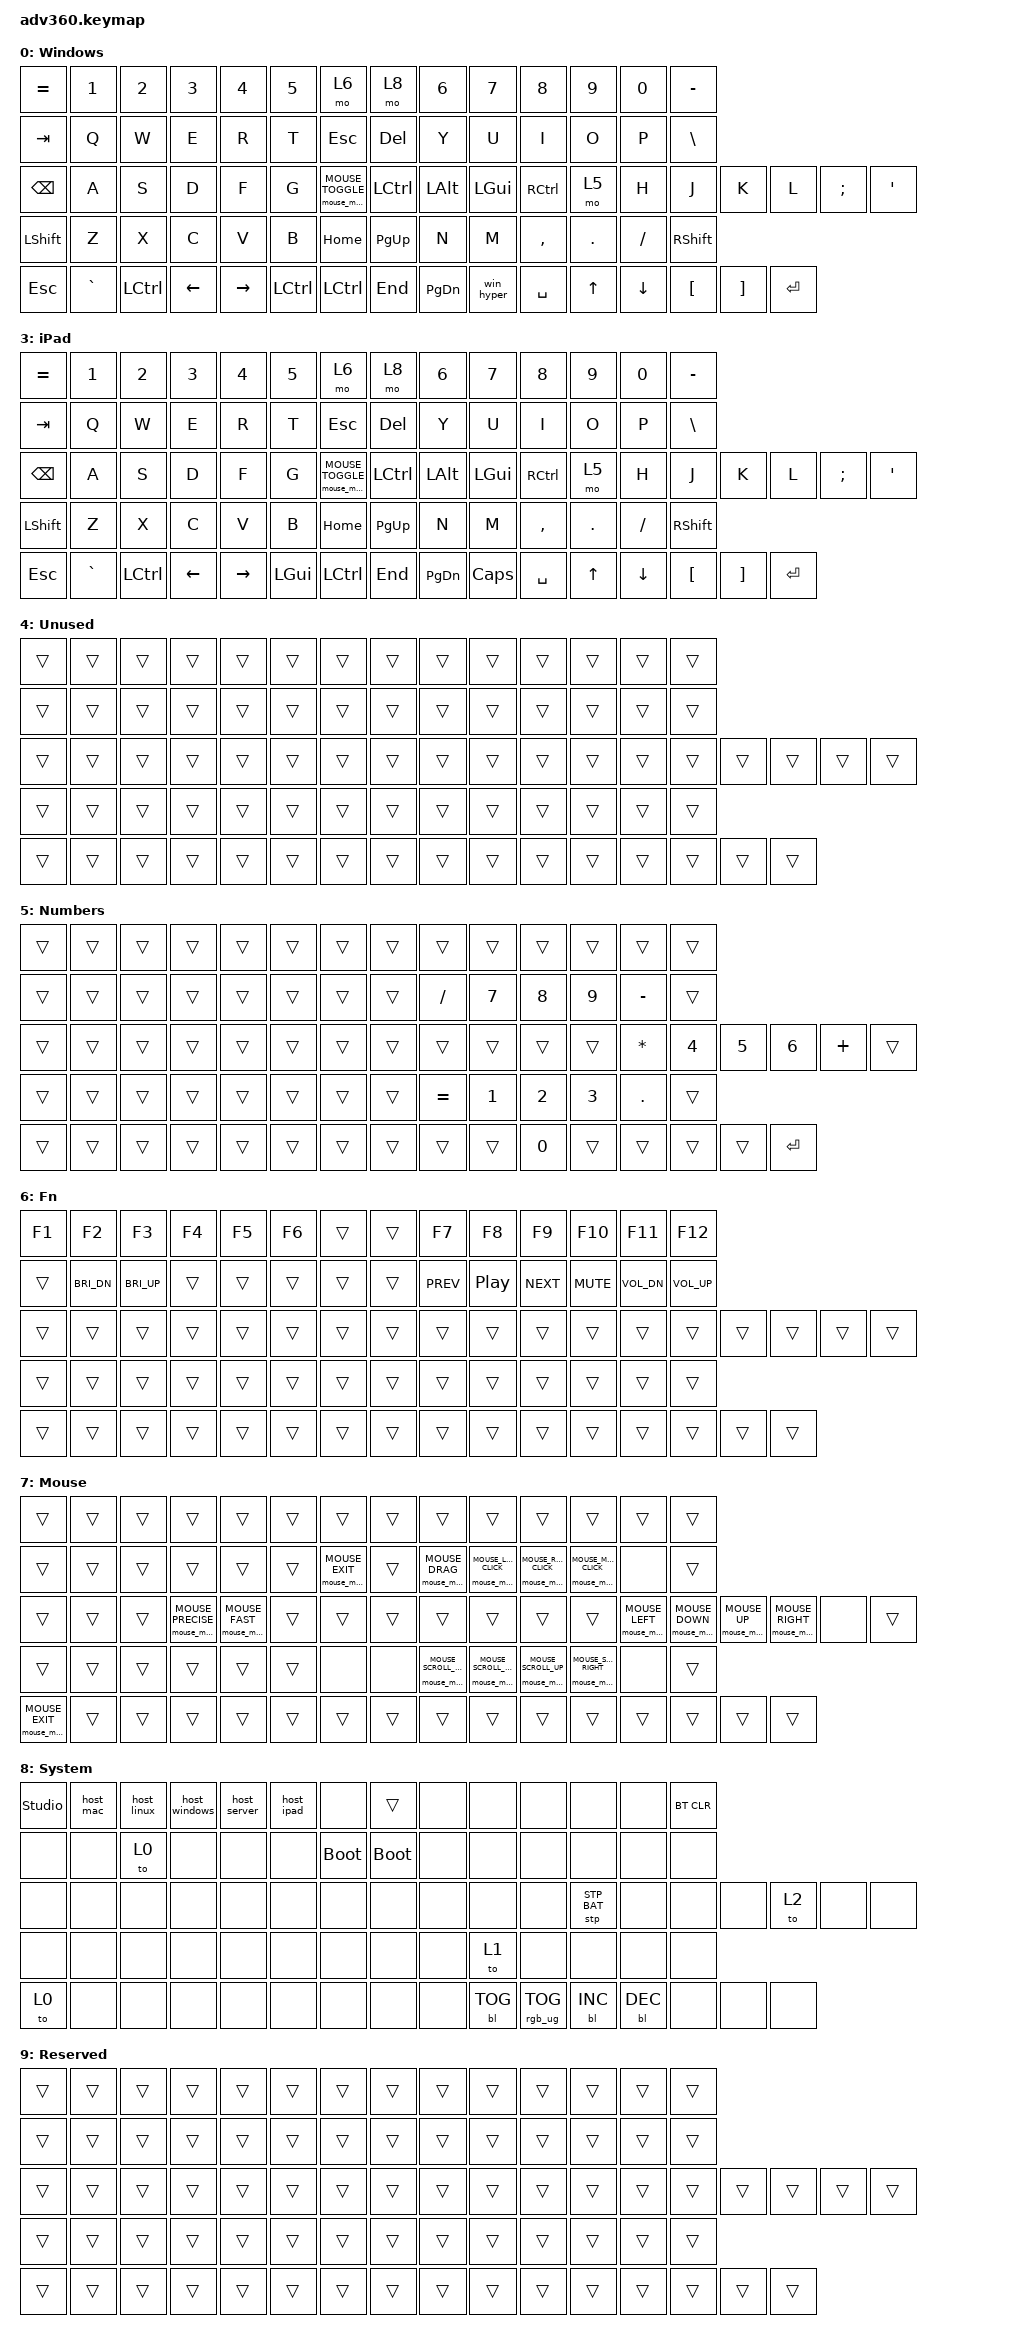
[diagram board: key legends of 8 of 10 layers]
// USER-APPROVED LAYOUT: device keys 1=Mac, 2=Linux, 3=Windows, 4=Linux server, 5=iPad.
// The boot default is Windows (no GUI in Hyper). Reselect a device after power-on.
// No tap-hold timing, no letter chords, Mouse is toggled; other utility layers are momentary.
#include <dt-bindings/zmk/stp.h>
#include <behaviors.dtsi>
#include <dt-bindings/zmk/backlight.h>
#include <dt-bindings/zmk/bt.h>
#include <dt-bindings/zmk/keys.h>
#include <dt-bindings/zmk/pointing.h>
#include <dt-bindings/zmk/mouse-mode.h>
#include <dt-bindings/zmk/rgb.h>

/ {
    mouse_precise_listener {
        compatible = "zmk,input-listener";
        device = <&mouse_precise_motion>;
    };
    mouse_fast_listener {
        compatible = "zmk,input-listener";
        device = <&mouse_fast_motion>;
    };
    behaviors {
        mouse_precise_motion: mouse_precise_motion {
            compatible = "zmk,behavior-input-two-axis";
            #binding-cells = <1>;
            x-input-code = <INPUT_REL_X>;
            y-input-code = <INPUT_REL_Y>;
            time-to-max-speed-ms = <0>;
            acceleration-exponent = <0>;
        };
        mouse_fast_motion: mouse_fast_motion {
            compatible = "zmk,behavior-input-two-axis";
            #binding-cells = <1>;
            x-input-code = <INPUT_REL_X>;
            y-input-code = <INPUT_REL_Y>;
            time-to-max-speed-ms = <0>;
            acceleration-exponent = <0>;
        };
        mouse_mode: mouse_mode {
            compatible = "zmk,behavior-mouse-mode";
            #binding-cells = <1>;
            layer = <7>;
            movement-behavior = <&mmv>;
            precise-behavior = <&mouse_precise_motion>;
            fast-behavior = <&mouse_fast_motion>;
            scroll-behavior = <&msc>;
        };
    };
    macros {
        // Hold real modifiers until the thumb is released. Modified F24 uses
        // implicit modifiers, which ZMK clears when another key is pressed.
        win_hyper: win_hyper {
            compatible = "zmk,behavior-macro";
            #binding-cells = <0>;
            wait-ms = <0>;
            tap-ms = <0>;
            bindings = <&macro_press &kp LCTRL &kp LSHFT &kp LALT &kp F24>,
                       <&macro_pause_for_release>,
                       <&macro_release &kp F24 &kp LALT &kp LSHFT &kp LCTRL>;
        };
        host_mac: host_mac {
            compatible = "zmk,behavior-macro";
            #binding-cells = <0>;
            wait-ms = <0>;
            tap-ms = <0>;
            // Release drag before changing the Bluetooth destination.
            bindings = <&macro_wait_time 50 &mouse_mode MOUSE_EXIT>,
                       <&macro_wait_time 0 &bt BT_SEL 0>, <&to 1>;
        };
        host_linux: host_linux {
            compatible = "zmk,behavior-macro";
            #binding-cells = <0>;
            wait-ms = <0>;
            tap-ms = <0>;
            // Release drag before changing the Bluetooth destination.
            bindings = <&macro_wait_time 50 &mouse_mode MOUSE_EXIT>,
                       <&macro_wait_time 0 &bt BT_SEL 1>, <&to 2>;
        };
        host_windows: host_windows {
            compatible = "zmk,behavior-macro";
            #binding-cells = <0>;
            wait-ms = <0>;
            tap-ms = <0>;
            // Release drag before changing the Bluetooth destination.
            bindings = <&macro_wait_time 50 &mouse_mode MOUSE_EXIT>,
                       <&macro_wait_time 0 &bt BT_SEL 2>, <&to 0>;
        };
        host_server: host_server {
            compatible = "zmk,behavior-macro";
            #binding-cells = <0>;
            wait-ms = <0>;
            tap-ms = <0>;
            // Release drag before changing the Bluetooth destination.
            bindings = <&macro_wait_time 50 &mouse_mode MOUSE_EXIT>,
                       <&macro_wait_time 0 &bt BT_SEL 3>, <&to 2>;
        };
        host_ipad: host_ipad {
            compatible = "zmk,behavior-macro";
            #binding-cells = <0>;
            wait-ms = <0>;
            tap-ms = <0>;
            // Slot 5 owns the iPad base; release mouse actions before switching.
            bindings = <&macro_wait_time 50 &mouse_mode MOUSE_EXIT>,
                       <&macro_wait_time 0 &bt BT_SEL 4>, <&to 3>;
        };
    };
    keymap {
        compatible = "zmk,keymap";
        windows {
            display-name = "Windows";
            bindings = <
                &kp EQUAL  &kp N1  &kp N2  &kp N3  &kp N4  &kp N5  &mo 6  &mo 8  &kp N6  &kp N7  &kp N8  &kp N9  &kp N0  &kp MINUS
                &kp TAB  &kp Q  &kp W  &kp E  &kp R  &kp T  &kp ESCAPE  &kp DELETE  &kp Y  &kp U  &kp I  &kp O  &kp P  &kp BSLH
                &kp BACKSPACE  &kp A  &kp S  &kp D  &kp F  &kp G  &mouse_mode MOUSE_TOGGLE  &kp LCTRL  &kp LALT  &kp LGUI  &kp RCTRL  &mo 5  &kp H  &kp J  &kp K  &kp L  &kp SEMI  &kp SQT
                &kp LSHFT  &kp Z  &kp X  &kp C  &kp V  &kp B  &kp HOME  &kp PG_UP  &kp N  &kp M  &kp COMMA  &kp DOT  &kp FSLH  &kp RSHFT
                &kp ESCAPE  &kp GRAVE  &kp LCTRL  &kp LEFT  &kp RIGHT  &kp LCTRL  &kp LCTRL  &kp END  &kp PG_DN  &win_hyper  &kp SPACE  &kp UP  &kp DOWN  &kp LBKT  &kp RBKT  &kp RETURN
            >;
        };
        macos {
            display-name = "Mac";
            bindings = <
                &kp EQUAL  &kp N1  &kp N2  &kp N3  &kp N4  &kp N5  &mo 6  &mo 8  &kp N6  &kp N7  &kp N8  &kp N9  &kp N0  &kp MINUS
                &kp TAB  &kp Q  &kp W  &kp E  &kp R  &kp T  &kp ESCAPE  &kp DELETE  &kp Y  &kp U  &kp I  &kp O  &kp P  &kp BSLH
                &kp BACKSPACE  &kp A  &kp S  &kp D  &kp F  &kp G  &mouse_mode MOUSE_TOGGLE  &kp LCTRL  &kp LALT  &kp LGUI  &kp RCTRL  &mo 5  &kp H  &kp J  &kp K  &kp L  &kp SEMI  &kp SQT
                &kp LSHFT  &kp Z  &kp X  &kp C  &kp V  &kp B  &kp HOME  &kp PG_UP  &kp N  &kp M  &kp COMMA  &kp DOT  &kp FSLH  &kp RSHFT
                &kp ESCAPE  &kp GRAVE  &kp LCTRL  &kp LEFT  &kp RIGHT  &kp LGUI  &kp LCTRL  &kp END  &kp PG_DN  &kp LS(LC(LA(LGUI)))  &kp SPACE  &kp UP  &kp DOWN  &kp LBKT  &kp RBKT  &kp RETURN
            >;
        };
        linux {
            display-name = "Linux";
            bindings = <
                &kp EQUAL  &kp N1  &kp N2  &kp N3  &kp N4  &kp N5  &mo 6  &mo 8  &kp N6  &kp N7  &kp N8  &kp N9  &kp N0  &kp MINUS
                &kp TAB  &kp Q  &kp W  &kp E  &kp R  &kp T  &kp ESCAPE  &kp DELETE  &kp Y  &kp U  &kp I  &kp O  &kp P  &kp BSLH
                &kp BACKSPACE  &kp A  &kp S  &kp D  &kp F  &kp G  &mouse_mode MOUSE_TOGGLE  &kp LCTRL  &kp LALT  &kp LGUI  &kp RCTRL  &mo 5  &kp H  &kp J  &kp K  &kp L  &kp SEMI  &kp SQT
                &kp LSHFT  &kp Z  &kp X  &kp C  &kp V  &kp B  &kp HOME  &kp PG_UP  &kp N  &kp M  &kp COMMA  &kp DOT  &kp FSLH  &kp RSHFT
                &kp ESCAPE  &kp GRAVE  &kp LCTRL  &kp LEFT  &kp RIGHT  &kp LCTRL  &kp LCTRL  &kp END  &kp PG_DN  &kp LS(LC(LA(LGUI)))  &kp SPACE  &kp UP  &kp DOWN  &kp LBKT  &kp RBKT  &kp RETURN
            >;
        };
        ipados {
            display-name = "iPad";
            // Right Hyper thumb becomes Globe via iPad Modifier Keys: Caps Lock -> Globe.
            // CAPS carrier preserves BASIC consumer reports and all other hosts.
            bindings = <
                &kp EQUAL  &kp N1  &kp N2  &kp N3  &kp N4  &kp N5  &mo 6  &mo 8  &kp N6  &kp N7  &kp N8  &kp N9  &kp N0  &kp MINUS
                &kp TAB  &kp Q  &kp W  &kp E  &kp R  &kp T  &kp ESCAPE  &kp DELETE  &kp Y  &kp U  &kp I  &kp O  &kp P  &kp BSLH
                &kp BACKSPACE  &kp A  &kp S  &kp D  &kp F  &kp G  &mouse_mode MOUSE_TOGGLE  &kp LCTRL  &kp LALT  &kp LGUI  &kp RCTRL  &mo 5  &kp H  &kp J  &kp K  &kp L  &kp SEMI  &kp SQT
                &kp LSHFT  &kp Z  &kp X  &kp C  &kp V  &kp B  &kp HOME  &kp PG_UP  &kp N  &kp M  &kp COMMA  &kp DOT  &kp FSLH  &kp RSHFT
                &kp ESCAPE  &kp GRAVE  &kp LCTRL  &kp LEFT  &kp RIGHT  &kp LGUI  &kp LCTRL  &kp END  &kp PG_DN  &kp CAPSLOCK  &kp SPACE  &kp UP  &kp DOWN  &kp LBKT  &kp RBKT  &kp RETURN
            >;
        };
        unused_4 {
            display-name = "Unused";
            // Keep this slot active: Legacy omits status="reserved" layers.
            bindings = <
                &trans  &trans  &trans  &trans  &trans  &trans  &trans  &trans  &trans  &trans  &trans  &trans  &trans  &trans  &trans  &trans  &trans  &trans  &trans  &trans  &trans  &trans  &trans  &trans  &trans  &trans  &trans  &trans  &trans  &trans  &trans  &trans  &trans  &trans  &trans  &trans  &trans  &trans  &trans  &trans  &trans  &trans  &trans  &trans  &trans  &trans  &trans  &trans  &trans  &trans  &trans  &trans  &trans  &trans  &trans  &trans  &trans  &trans  &trans  &trans  &trans  &trans  &trans  &trans  &trans  &trans  &trans  &trans  &trans  &trans  &trans  &trans  &trans  &trans  &trans  &trans
            >;
        };
        numbers {
            display-name = "Numbers";
            bindings = <
                &trans  &trans  &trans  &trans  &trans  &trans  &trans  &trans  &trans  &trans  &trans  &trans  &trans  &trans
                &trans  &trans  &trans  &trans  &trans  &trans  &trans  &trans  &kp FSLH  &kp N7  &kp N8  &kp N9  &kp MINUS  &trans
                &trans  &trans  &trans  &trans  &trans  &trans  &trans  &trans  &trans  &trans  &trans  &trans  &kp ASTERISK  &kp N4  &kp N5  &kp N6  &kp PLUS  &trans
                &trans  &trans  &trans  &trans  &trans  &trans  &trans  &trans  &kp EQUAL  &kp N1  &kp N2  &kp N3  &kp DOT  &trans
                &trans  &trans  &trans  &trans  &trans  &trans  &trans  &trans  &trans  &trans  &kp N0  &trans  &trans  &trans  &trans  &kp RETURN
            >;
        };
        function {
            display-name = "Fn";
            bindings = <
                &kp F1  &kp F2  &kp F3  &kp F4  &kp F5  &kp F6  &trans  &trans  &kp F7  &kp F8  &kp F9  &kp F10  &kp F11  &kp F12
                &trans  &kp C_BRI_DN  &kp C_BRI_UP  &trans  &trans  &trans  &trans  &trans  &kp C_PREV  &kp C_PLAY_PAUSE  &kp C_NEXT  &kp C_MUTE  &kp C_VOL_DN  &kp C_VOL_UP
                &trans  &trans  &trans  &trans  &trans  &trans  &trans  &trans  &trans  &trans  &trans  &trans  &trans  &trans  &trans  &trans  &trans  &trans
                &trans  &trans  &trans  &trans  &trans  &trans  &trans  &trans  &trans  &trans  &trans  &trans  &trans  &trans
                &trans  &trans  &trans  &trans  &trans  &trans  &trans  &trans  &trans  &trans  &trans  &trans  &trans  &trans  &trans  &trans
            >;
        };
        pointer {
            display-name = "Mouse";
            bindings = <
                &trans  &trans  &trans  &trans  &trans  &trans  &trans  &trans  &trans  &trans  &trans  &trans  &trans  &trans
                &trans  &trans  &trans  &trans  &trans  &trans  &mouse_mode MOUSE_EXIT  &trans  &mouse_mode MOUSE_DRAG  &mouse_mode MOUSE_LEFT_CLICK  &mouse_mode MOUSE_RIGHT_CLICK  &mouse_mode MOUSE_MIDDLE_CLICK  &none  &trans
                &trans  &trans  &trans  &mouse_mode MOUSE_PRECISE  &mouse_mode MOUSE_FAST  &trans  &trans  &trans  &trans  &trans  &trans  &trans  &mouse_mode MOUSE_LEFT  &mouse_mode MOUSE_DOWN  &mouse_mode MOUSE_UP  &mouse_mode MOUSE_RIGHT  &none  &trans
                &trans  &trans  &trans  &trans  &trans  &trans  &none  &none  &mouse_mode MOUSE_SCROLL_LEFT  &mouse_mode MOUSE_SCROLL_DOWN  &mouse_mode MOUSE_SCROLL_UP  &mouse_mode MOUSE_SCROLL_RIGHT  &none  &trans
                &mouse_mode MOUSE_EXIT  &trans  &trans  &trans  &trans  &trans  &trans  &trans  &trans  &trans  &trans  &trans  &trans  &trans  &trans  &trans
            >;
        };
        system {
            display-name = "System";
            bindings = <
                &studio_unlock  &host_mac  &host_linux  &host_windows  &host_server  &host_ipad  &none  &trans  &none  &none  &none  &none  &none  &bt BT_CLR
                &none  &none  &to 0  &none  &none  &none  &bootloader  &bootloader  &none  &none  &none  &none  &none  &none
                &none  &none  &none  &none  &none  &none  &none  &none  &none  &none  &none  &stp STP_BAT  &none  &none  &none  &to 2  &none  &none
                &none  &none  &none  &none  &none  &none  &none  &none  &none  &to 1  &none  &none  &none  &none
                &to 0  &none  &none  &none  &none  &none  &none  &none  &none  &bl BL_TOG  &rgb_ug RGB_TOG  &bl BL_INC  &bl BL_DEC  &none  &none  &none
            >;
        };
        reserved {
            display-name = "Reserved";
            // Keep this slot active: Legacy omits status="reserved" layers.
            bindings = <
                &trans  &trans  &trans  &trans  &trans  &trans  &trans  &trans  &trans  &trans  &trans  &trans  &trans  &trans  &trans  &trans  &trans  &trans  &trans  &trans  &trans  &trans  &trans  &trans  &trans  &trans  &trans  &trans  &trans  &trans  &trans  &trans  &trans  &trans  &trans  &trans  &trans  &trans  &trans  &trans  &trans  &trans  &trans  &trans  &trans  &trans  &trans  &trans  &trans  &trans  &trans  &trans  &trans  &trans  &trans  &trans  &trans  &trans  &trans  &trans  &trans  &trans  &trans  &trans  &trans  &trans  &trans  &trans  &trans  &trans  &trans  &trans  &trans  &trans  &trans  &trans
            >;
        };
    };
};
